# nRF7140_graphics register map
Vendor: Nordic Semiconductor; Series: nRF71; File version: 1
CPU: CM33 r0p4, little endian, MPU, FPU, 3 interrupt priority bits, 480 interrupts
Registers are 32-bit, read-write, reset 0x0 unless marked. A register's access mark holds for its fields unless they carry their own. Offsets are from the block's base; [hi:lo] are bit positions; lines under a group give offsets from that group; {n}, {i} and the like mark numbered series; 'fields as' and 'values as' point back to an identical list.

## GLOBAL_QSPI110_NS — Quad serial peripheral interface 0
Base 0x4F0A3000
Same registers: GLOBAL_QSPI111_NS 0x4F0A5000, GLOBAL_QSPI110_S 0x5F0A3000, GLOBAL_QSPI111_S 0x5F0A5000
0x00 TASKS_START wo — Start operation.
  [0] TASKS_START
    1=Trigger task
0x04 TASKS_STOP wo — Stop operation.
  [0] TASKS_STOP
    1=Trigger task
0x08 TASKS_DMA group — Peripheral tasks.
  0x00 TXACK wo — Task to indicate the DMA for Tx is completed (to the third party IP)
    [0] TXACK
      1=Trigger task
  0x04 RXACK wo — Task to indicate the DMA for Rx is completed (to the third party IP)
    [0] RXACK
      1=Trigger task
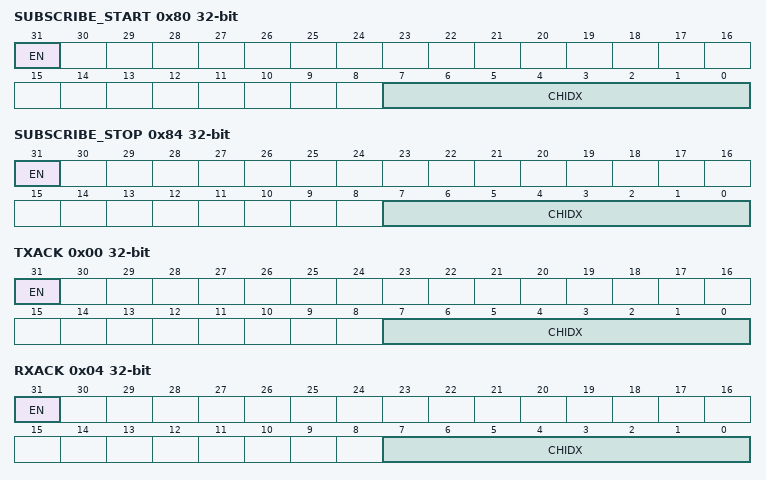
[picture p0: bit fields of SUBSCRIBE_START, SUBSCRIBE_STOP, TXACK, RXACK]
0x80 SUBSCRIBE_START — Subscribe configuration for task START
  [31] EN
    0=Disabled (Disable subscription); 1=Enabled (Enable subscription)
  [7:0] CHIDX — DPPI channel that task START will subscribe to
0x84 SUBSCRIBE_STOP — Subscribe configuration for task STOP
  [31] EN
    values as SUBSCRIBE_START.EN
  [7:0] CHIDX — DPPI channel that task STOP will subscribe to
0x88 SUBSCRIBE_DMA group — Subscribe configuration for tasks
  0x00 TXACK — Subscribe configuration for task DMA.TXACK
    [31] EN
      values as SUBSCRIBE_START.EN
    [7:0] CHIDX — DPPI channel that task DMA.TXACK will subscribe to
  0x04 RXACK — Subscribe configuration for task DMA.RXACK
    [31] EN
      values as SUBSCRIBE_START.EN
    [7:0] CHIDX — DPPI channel that task DMA.RXACK will subscribe to
0x100 EVENTS_DMA group — Peripheral events.
  0x00 TX — Event requesting DMA for Tx (from the third party IP)
    [0] TX
      0=NotGenerated (Event not generated); 1=Generated (Event generated)
  0x04 RX — Event requesting DMA for Rx (from the third party IP)
    [0] RX
      values as EVENTS_DMA.TX.TX
0x180 PUBLISH_DMA group — Publish configuration for events
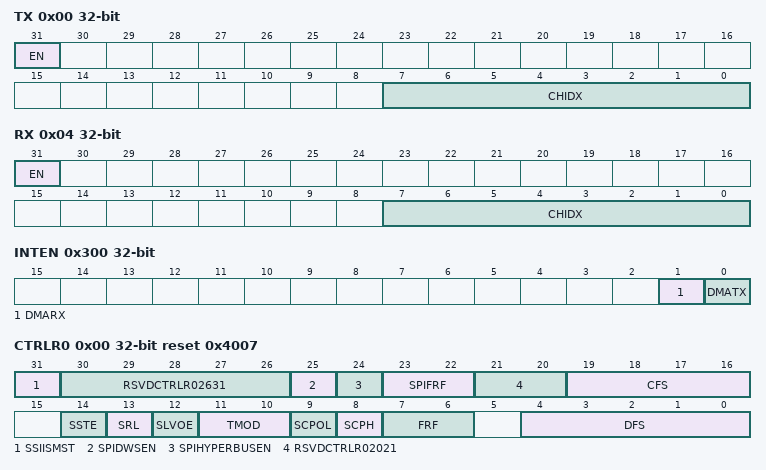
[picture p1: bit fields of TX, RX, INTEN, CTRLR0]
  0x00 TX — Publish configuration for event DMA.TX
    [31] EN
      0=Disabled (Disable publishing); 1=Enabled (Enable publishing)
    [7:0] CHIDX — DPPI channel that event DMA.TX will publish to
  0x04 RX — Publish configuration for event DMA.RX
    [31] EN
      values as PUBLISH_DMA.TX.EN
    [7:0] CHIDX — DPPI channel that event DMA.RX will publish to
0x300 INTEN — Enable or disable interrupt
  [1] DMARX — Enable or disable interrupt for event DMARX
    0=Disabled; 1=Enabled
  [0] DMATX — Enable or disable interrupt for event DMATX
    0=Disabled; 1=Enabled
0x800 CORE group — Unspecified
  0x00 CTRLR0 reset 0x4007 — This register controls the serial data transfer.
    [31] SSIISMST ro — This field selects if DWC_ssi is working in Master or Slave mode
      0=SLAVE (Unspecified); 1=MASTER (Unspecified)
    [30:26] RSVDCTRLR02631 ro — Reserved bits - read as zero
    [25] SPIDWSEN — Enable Dynamic wait states in SPI mode of operation. This field is only applicable when CTRLR0.FRF is set to 0 (Motorola SPI Frame Format).
      0=DISABLE (Unspecified); 1=ENABLE (Unspecified)
    [24] SPIHYPERBUSEN ro — SPI Hyperbus Frame format enable.
      0=DISABLE (Unspecified); 1=ENABLE (Unspecified)
    [23:22] SPIFRF — SPI Frame Format
      0=SPI_STANDARD (Unspecified); 1=SPI_DUAL (Unspecified); 2=SPI_QUAD (Unspecified); 3=SPI_OCTAL (Unspecified)
    [21:20] RSVDCTRLR02021 ro — Reserved bits - read as zero
    [19:16] CFS — Control Frame Size.
      {v}=SIZE_{v+1:02}_BIT (Unspecified) (v=0..15)
    [14] SSTE — Slave Select Toggle Enable.
      0=TOGGLE_DISABLE (Unspecified); 1=TOGGLE_EN (Unspecified)
    [13] SRL — Shift Register Loop.
      0=NORMAL_MODE (Unspecified); 1=TESTING_MODE (Unspecified)
    [12] SLVOE — Slave Output Enable.
      0=ENABLED (Unspecified); 1=DISABLED (Unspecified)
    [11:10] TMOD — Transfer Mode.
      0=TX_AND_RX (Unspecified); 1=TX_ONLY (Unspecified); 2=RX_ONLY (Unspecified); 3=EEPROM_READ (Unspecified)
    [9] SCPOL ro — Serial Clock Polarity.
      0=INACTIVE_HIGH (Unspecified); 1=INACTIVE_LOW (Unspecified)
    [8] SCPH ro — Serial Clock Phase.
      0=MIDDLE_BIT (Unspecified); 1=START_BIT (Unspecified)
    [7:6] FRF ro — Frame Format.
      0=SPI (Unspecified); 1=SSP (Unspecified); 2=MICROWIRE (Unspecified)
    [4:0] DFS — Data Frame Size.
      {v}=DFS_{v+1:02}_BIT (Unspecified) (v=0..31)
  0x04 CTRLR1 — This register exists only when the DWC_ssi is configured as a master device.
    [15:0] NDF — Number of Data Frames.
  0x08 SSIENR — This register enables and disables the DWC_ssi.
    [0] SSICEN — SSI Enable.
      0=DISABLE (Unspecified); 1=ENABLED (Unspecified)
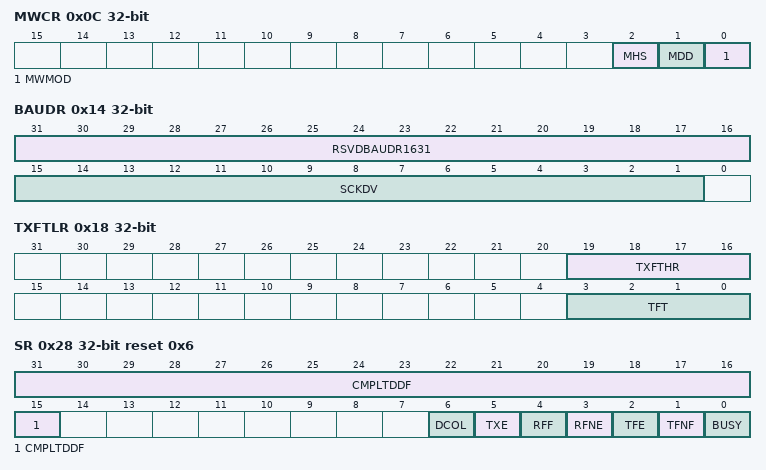
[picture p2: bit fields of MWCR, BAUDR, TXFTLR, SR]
  0x0C MWCR — This register controls the direction of the data word for the half-duplex Microwire serial protocol.
    [2] MHS — Microwire Handshaking.
      0=DISABLE (Unspecified); 1=ENABLED (Unspecified)
    [1] MDD — Microwire Control.
      0=RECEIVE (Unspecified); 1=TRANSMIT (Unspecified)
    [0] MWMOD — Microwire Transfer Mode.
      0=NON_SEQUENTIAL (Unspecified); 1=SEQUENTIAL (Unspecified)
  0x10 SER — Serial slave select
    [1:0] SER — Slave Select Enable Flag.
  0x14 BAUDR — Baudrate
    [31:16] RSVDBAUDR1631 ro — Reserved bits - read as zero
    [15:1] SCKDV — SSI Clock Divider.
  0x18 TXFTLR — This register controls the threshold value for the transmit FIFO memory.
    [19:16] TXFTHR — Transfer start FIFO level.
    [3:0] TFT — Transmit FIFO Threshold.
  0x1C RXFTLR — This register controls the threshold value for the receive FIFO memory.
    [3:0] RFT — Receive FIFO Threshold.
  0x20 TXFLR — This register contains the number of valid data entries in the transmit FIFO memory.
    [4:0] TXTFL ro — Transmit FIFO Level.
  0x24 RXFLR — This register contains the number of valid data entries in the receive FIFO memory.
    [4:0] RXTFL ro — Receive FIFO Level.
  0x28 SR reset 0x6 — Transfer Status Register
    [31:15] CMPLTDDF ro — Completed Data frames
    [6] DCOL ro — Data Collision Error.
      0=NO_ERROR_CONDITION (Unspecified); 1=TX_COLLISION_ERROR (Unspecified)
    [5] TXE ro — Transmission Error.
      0=NO_ERROR (Unspecified); 1=TX_ERROR (Unspecified)
    [4] RFF ro — Receive FIFO Full.
      0=NOT_FULL (Unspecified); 1=FULL (Unspecified)
    [3] RFNE ro — Receive FIFO Not Empty.
      0=EMPTY (Unspecified); 1=NOT_EMPTY (Unspecified)
    [2] TFE ro — Transmit FIFO Empty.
      0=NOT_EMPTY (Unspecified); 1=EMPTY (Unspecified)
    [1] TFNF ro — Transmit FIFO Not Full.
      0=FULL (Unspecified); 1=NOT_FULL (Unspecified)
    [0] BUSY ro — SSI Busy Flag.
      0=INACTIVE (Unspecified); 1=ACTIVE (Unspecified)
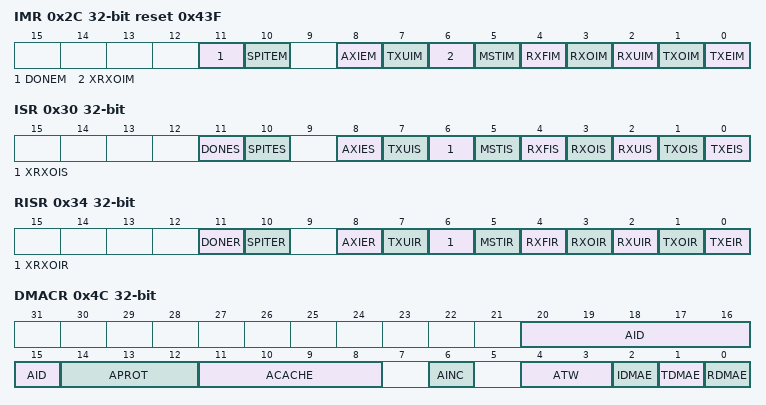
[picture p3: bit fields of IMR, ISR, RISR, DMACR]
  0x2C IMR reset 0x43F — Interrupt Mask Register
    [all] fields
      0=MASKED (Unspecified); 1=UNMASKED (Unspecified)
    [11] DONEM ro — SSI Done Interrupt Mask
    [10] SPITEM — SPI Transmit Error Interrupt Mask
    [8] AXIEM ro — AXI Error Interrupt Mask
    [7] TXUIM ro — Transmit FIFO Underflow Interrupt Mask
    [6] XRXOIM ro — XIP Receive FIFO Overflow Interrupt Mask
    [5] MSTIM — Multi-Master Contention Interrupt Mask. This bit field is not present if the DWC_ssi is configured as a serial-master device.
    [4] RXFIM — Receive FIFO Full Interrupt Mask
    [3] RXOIM — Receive FIFO Overflow Interrupt Mask
    [2] RXUIM — Receive FIFO Underflow Interrupt Mask
    [1] TXOIM — Transmit FIFO Overflow Interrupt Mask
    [0] TXEIM — Transmit FIFO Empty Interrupt Mask
  0x30 ISR — Interrupt Status Register
    [all] fields
      0=INACTIVE (Unspecified); 1=ACTIVE (Unspecified)
    [11] DONES ro — SSI Done Interrupt Status
    [10] SPITES ro — SPI Transmit Error Interrupt
    [8] AXIES ro — AXI Error Interrupt Status
    [7] TXUIS ro — Transmit FIFO Underflow Interrupt Status
    [6] XRXOIS ro — XIP Receive FIFO Overflow Interrupt Status
    [5] MSTIS ro — Multi-Master Contention Interrupt Status. This bit field is not present
    [4] RXFIS ro — Receive FIFO Full Interrupt Status
    [3] RXOIS ro — Receive FIFO Overflow Interrupt Status
    [2] RXUIS ro — Receive FIFO Underflow Interrupt Status
    [1] TXOIS ro — Transmit FIFO Overflow Interrupt Status
    [0] TXEIS ro — Transmit FIFO Empty Interrupt Status
  0x34 RISR — Raw Interrupt Status Register
    [all] fields
      0=INACTIVE (Unspecified); 1=ACTIVE (Unspecified)
    [11] DONER ro — SSI Done Interrupt Raw Status
    [10] SPITER ro — SPI Transmit Error Interrupt status.
    [8] AXIER ro — AXI Error Interrupt Raw Status
    [7] TXUIR ro — Transmit FIFO Underflow Interrupt Raw Status
    [6] XRXOIR ro — XIP Receive FIFO Overflow Raw Interrupt Status
    [5] MSTIR ro — Multi-Master Contention Raw Interrupt Status. This bit field is not present if the DWC_ssi is configured as a serial-slave device.
    [4] RXFIR ro — Receive FIFO Full Raw Interrupt Status
    [3] RXOIR ro — Receive FIFO Overflow Raw Interrupt Status
    [2] RXUIR ro — Receive FIFO Underflow Raw Interrupt Status
    [1] TXOIR ro — Transmit FIFO Overflow Raw Interrupt Status
    [0] TXEIR ro — Transmit FIFO Empty Raw Interrupt Status
  0x38 TXEICR — Transmit FIFO Error Interrupt Clear Register
    [0] TXEICR ro — Clear Transmit FIFO Overflow/Underflow Interrupt.
  0x3C RXOICR — Receive FIFO Overflow Interrupt Clear Register
    [0] RXOICR ro — Clear Receive FIFO Overflow Interrupt.
  0x40 RXUICR — Receive FIFO Underflow Interrupt Clear Register
    [0] RXUICR ro — Clear Receive FIFO Underflow Interrupt.
  0x44 MSTICR — Multi-Master Interrupt Clear Register
    [0] MSTICR ro — Clear Multi-Master Contention Interrupt.
  0x48 ICR — Interrupt Clear Register
    [0] ICR ro — Clear Interrupts.
  0x4C DMACR — DMA Control Register.
    [20:15] AID ro — AXI awid/arid signal value.
    [14:12] APROT ro — AXI arprot/awprot signal value.
    [11:8] ACACHE ro — AXI arcache/awcache signal value.
    [6] AINC ro — Address Increment. Indicates whether to increment the AXI address on every transfer.
    [4:3] ATW ro — AXI transfer width for DMA transfers mapped to arsize/awsize. This value must be less than or equal to SSIC_AXI_DW. Values:
    [2] IDMAE ro — Internal DMA Enable. This bit should be enabled only when CTRLR0.FRF = 0 (Motorola SPI) and CTRLR0.SPI_FRF FIXME GT 0.
    [1] TDMAE — Transmit DMA Enable. This bit enables/disables the transmit FIFO DMA channel.
      0=DISABLE (Unspecified); 1=ENABLED (Unspecified)
    [0] RDMAE — Receive DMA Enable. This bit enables/disables the receive FIFO DMA channel.
      0=DISABLE (Unspecified); 1=ENABLED (Unspecified)
  0x50 DMATDLR — DMA Transmit Data Level Register
    [3:0] DMATDL — Transmit Data Level. This bit field controls the level at which a DMA request is made by the transmit logic. It is equal to the watermark level; that is, the dma_tx_req signal is generated when the number of valid data entries in the transmit FIFO is equal to or below this field value, and TDMAE = 1.
  0x54 DMARDLR — DMA Receive Data Level Register
    [3:0] DMARDL — Receive Data Level. This bit field controls the level at which a DMA request is made by the receive logic. The watermark level = DMARDL+1; that is, dma_rx_req is generated when the number of valid data entries in the receive FIFO is equal to or above this field value + 1, and RDMAE=1.
  0x58 IDR reset 0x51535049 — This register contains the peripherals identification code, which is written into the register at configuration time using coreConsultant.
    [31:0] IDCODE ro — Identification code. The register contains the peripherals identification code, which is written into the register at configuration time using CoreConsultant.
  0x5C SSICVERSIONID reset 0x3130332A — This read-only register stores the specific DWC_ssi component version.
    [31:0] SSICCOMPVERSION ro — Contains the hex representation of the Synopsys component version. Consists of ASCII value for each number in the version, followed by *. For example 31_30_33_2A represents the version 1.03*.
  {0x60+4j} DR0[{j}] (j=0..35) — Description collection: Data register [n]
    [31:0] DR — Data Register. When writing to this register, you must right-justify the data. Read data are automatically right-justified.
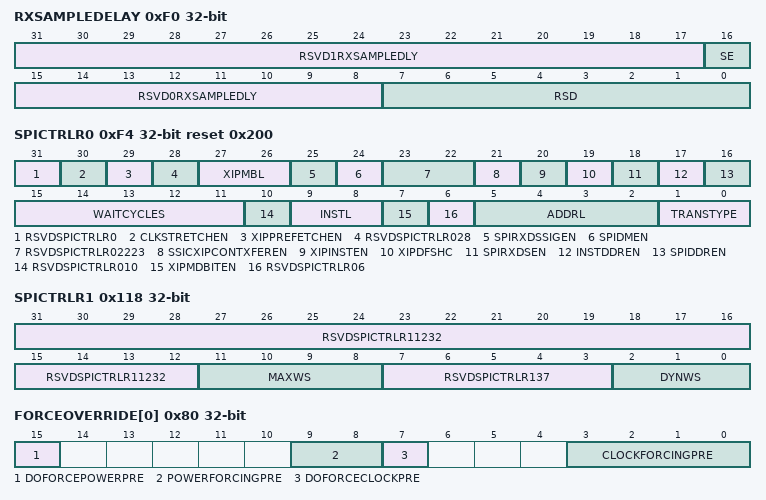
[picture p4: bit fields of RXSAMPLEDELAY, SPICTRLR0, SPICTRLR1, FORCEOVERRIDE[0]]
  0xF0 RXSAMPLEDELAY — Receive Data sample delay
    [31:17] RSVD1RXSAMPLEDLY ro — Reserved bits - read as zero
    [16] SE — Receive Data (rxd) Sampling Edge. This register is used to decide the sampling edge for RXD signal with ssi_clk. Then this bit is set to 1 then negative edge of ssi_clk will be used to sample the incoming data, otherwise positive edge will be used for sampling.
    [15:8] RSVD0RXSAMPLEDLY ro — Reserved bits - read as zero
    [7:0] RSD — Receive Data (rxd) Sample Delay. This register is used to delay the sample of the rxd input port. Each value
  0xF4 SPICTRLR0 reset 0x200 — SPI Control Register 0
    [31] RSVDSPICTRLR0 ro — Reserved bits - read as zero
    [30] CLKSTRETCHEN — Enables clock stretching capability in SPI transfers.
    [29] XIPPREFETCHEN ro — Enables XIP pre-fetch functionality in DWC_ssi.
    [28] RSVDSPICTRLR028 ro — Reserved bits - read as zero
    [27:26] XIPMBL ro — XIP Mode bits length. Sets the length of mode bits in XIP mode of operation. These bits are valid only when SPI_CTRLR0.XIP_MD_BIT_EN is set to 1.
      0=MBL_2 (Unspecified); 1=MBL_4 (Unspecified); 2=MBL_8 (Unspecified); 3=MBL_16 (Unspecified)
    [25] SPIRXDSSIGEN ro — Enable rxds signaling during address and command phase of Hypebus transfer.
    [24] SPIDMEN ro — SPI data mask enable bit.
    [23:22] RSVDSPICTRLR02223 ro — Reserved bits - read as zero
    [21] SSICXIPCONTXFEREN ro — Enable continuous transfer in XIP mode. If this bit is set to 1 then continuous transfer mode in XIP will be enabled, in this mode DWC_ssi will keep slave selected until a non-XIP transfer is detected on the AHB interface.
    [20] XIPINSTEN ro — XIP instruction enable bit. If this bit is set to 1 then XIP transfers will also have instruction phase. The instruction op-codes will be chosen from XIP_INCR_INST or XIP_WRAP_INST registers bases on AHB transfer type.
    [19] XIPDFSHC ro — Fix DFS for XIP transfers. If this bit is set to 1 then data frame size for XIP transfers will be fixed to the programmed value in CTRLR0.DFS. The number of data frames to fetch will be determined by HSIZE and HBURST signals. If this bit is set to 0 then data frame size and number of data frames to fetch will be determined by HSIZE and HBURST signals
    [18] SPIRXDSEN ro — Read data strobe enable bit. Once this bit is set to 1 DWC_ssi will use Read data strobe (rxds) to capture read data in DDR mode.
    [17] INSTDDREN ro — Instruction DDR Enable bit. This will enable Dual-data rate transfer for Instruction phase.
    [16] SPIDDREN ro — SPI DDR Enable bit. This will enable Dual-data rate transfers in Dual/Quad/Octal frame formats of SPI.
    [15:11] WAITCYCLES — Wait cycles in Dual/Quad/Octal mode between control frames transmit and data reception. Specified as number of SPI clock cycles.
    [10] RSVDSPICTRLR010 ro — Reserved bits - read as zero
    [9:8] INSTL — Dual/Quad/Octal mode instruction length in bits.
      0=INST_L0 (Unspecified); 1=INST_L4 (Unspecified); 2=INST_L8 (Unspecified); 3=INST_L16 (Unspecified)
    [7] XIPMDBITEN ro — Mode bits enable in XIP mode. If this bit is set to 1, then in XIP mode of operation DWC_ssi will insert mode bits after the address phase. These bits are set in register XIP_MODE_BITS register. The length of mode bits is always set to 8 bits.
    [6] RSVDSPICTRLR06 ro — Reserved bits - read as zero
    [5:2] ADDRL — This bit defines Length of Address to be transmitted. Only after this much bits are programmed in to the FIFO the transfer can begin.
      0=ADDR_L0 (Unspecified); 1=ADDR_L4 (Unspecified); 2=ADDR_L8 (Unspecified); 3=ADDR_L12 (Unspecified); 4=ADDR_L16 (Unspecified); 5=ADDR_L20 (Unspecified); 6=ADDR_L24 (Unspecified); 7=ADDR_L28 (Unspecified); 8=ADDR_L32 (Unspecified); 9=ADDR_L36 (Unspecified); 10=ADDR_L40 (Unspecified); 11=ADDR_L44 (Unspecified); 12=ADDR_L48 (Unspecified); 13=ADDR_L52 (Unspecified); 14=ADDR_L56 (Unspecified); 15=ADDR_L60 (Unspecified)
    [1:0] TRANSTYPE — Address and instruction transfer format.
      {v}=TT{v} (Unspecified) (v=0..3)
  0x118 SPICTRLR1 — SPI Control Register 1
    [31:12] RSVDSPICTRLR11232 ro — Reserved bits - Read Only
    [11:8] MAXWS — Maximum wait cycles allowed per transaction.
    [7:3] RSVDSPICTRLR137 ro — Reserved bits - Read Only
    [2:0] DYNWS — SPI Dynamic Wait states field.
  0x11C SPITECR — SPI Transmit Error Interrupt Clear Register
    [0] SPITECR ro — Clear SPI Transmit Error interrupt.
0xF00 PCGCSLAVE group — Unspecified
  {0x0+4j} PENALTY[{j}] (j=0..0) — Description collection: Penalty level for power/clock pair n
    [7:0] PENALTY — Penalty level
  {0x80+4j} FORCEOVERRIDE[{j}] (j=0..0) — Description collection: Force override of power/clock pair n
    [15] DOFORCEPOWERPRE, [9:8] POWERFORCINGPRE, [7] DOFORCECLOCKPRE, [3:0] CLOCKFORCINGPRE

## Notices in the file
Copyright (c) 2010 - 2022, Nordic Semiconductor ASA
All rights reserved.
Redistribution and use in source and binary forms, with or without modification,
are permitted provided that the following conditions are met:
1. Redistributions of source code must retain the above copyright notice, this
list of conditions and the following disclaimer.
2. Redistributions in binary form, except as embedded into a Nordic
Semiconductor ASA integrated circuit in a product or a software update for
such product, must reproduce the above copyright notice, this list of
conditions and the following disclaimer in the documentation and/or other
materials provided with the distribution.
3. Neither the name of Nordic Semiconductor ASA nor the names of its
contributors may be used to endorse or promote products derived from this
software without specific prior written permission.
4. This software, with or without modification, must only be used with a
Nordic Semiconductor ASA integrated circuit.
5. Any software provided in binary form under this license must not be reverse
engineered, decompiled, modified and/or disassembled.
THIS SOFTWARE IS PROVIDED BY NORDIC SEMICONDUCTOR ASA "AS IS" AND ANY EXPRESS
OR IMPLIED WARRANTIES, INCLUDING, BUT NOT LIMITED TO, THE IMPLIED WARRANTIES
OF MERCHANTABILITY, NONINFRINGEMENT, AND FITNESS FOR A PARTICULAR PURPOSE ARE
DISCLAIMED. IN NO EVENT SHALL NORDIC SEMICONDUCTOR ASA OR CONTRIBUTORS BE
LIABLE FOR ANY DIRECT, INDIRECT, INCIDENTAL, SPECIAL, EXEMPLARY, OR
CONSEQUENTIAL DAMAGES (INCLUDING, BUT NOT LIMITED TO, PROCUREMENT OF SUBSTITUTE
GOODS OR SERVICES; LOSS OF USE, DATA, OR PROFITS; OR BUSINESS INTERRUPTION)
HOWEVER CAUSED AND ON ANY THEORY OF LIABILITY, WHETHER IN CONTRACT, STRICT
LIABILITY, OR TORT (INCLUDING NEGLIGENCE OR OTHERWISE) ARISING IN ANY WAY OUT
OF THE USE OF THIS SOFTWARE, EVEN IF ADVISED OF THE POSSIBILITY OF SUCH DAMAGE.
